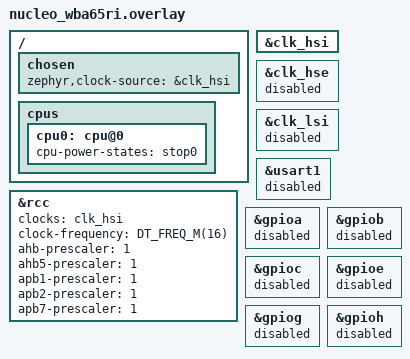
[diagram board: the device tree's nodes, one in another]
/*
 * SPDX-License-Identifier: Apache-2.0
 *
 * Copyright (c) 2023 STMicroelectronics
 */

/ {
	chosen {
        zephyr,clock-source = &clk_hsi;
    };

	cpus {
		cpu0: cpu@0 {
			cpu-power-states = <&stop0>;
		};
	};
};
&clk_hsi {
    status = "okay";
};
&clk_hse {
	status = "disabled";
};
/* Set HSI16 as clock source to use VOS0 - low power regulator range */
&rcc {
	clocks = <&clk_hsi>;
	clock-frequency = <DT_FREQ_M(16)>;
	ahb-prescaler = <1>;
	ahb5-prescaler = <1>;
	apb1-prescaler = <1>;
	apb2-prescaler = <1>;
	apb7-prescaler = <1>;
};

&clk_lsi {
	status = "disabled";
};

&usart1 {
	status = "disabled";
};

&gpioa {
    status = "disabled";
};
&gpiob {
    status = "disabled";
};
&gpioc {
    status = "disabled";
};
// &gpiod {
//     status = "disabled";
// };
&gpioe {
    status = "disabled";
};
&gpiog {
    status = "disabled";
};
&gpioh {
    status = "disabled";
};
